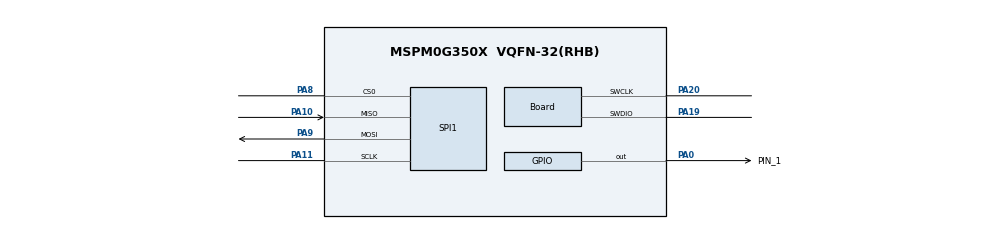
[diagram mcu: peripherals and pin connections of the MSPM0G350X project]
/**
 * @cliArgs --device "MSPM0G350X" --part "Default" --package "VQFN-32(RHB)" --product "mspm0_sdk@2.04.00.06"
 * @versions {"tool":"1.23.0+4000"}
 */

/**
 * Import the modules used in this configuration.
 */
const GPIO   = scripting.addModule("/ti/driverlib/GPIO", {}, false);
const GPIO1  = GPIO.addInstance();
const SPI    = scripting.addModule("/ti/driverlib/SPI", {}, false);
const SPI1   = SPI.addInstance();
const SYSCTL = scripting.addModule("/ti/driverlib/SYSCTL");

/**
 * Write custom configuration values to the imported modules.
 */
GPIO1.$name                              = "LED1";
GPIO1.associatedPins[0].$name            = "PIN_1";
GPIO1.associatedPins[0].internalResistor = "PULL_DOWN";
GPIO1.associatedPins[0].pin.$assign      = "PA0";

const Board                       = scripting.addModule("/ti/driverlib/Board", {}, false);
Board.peripheral.$assign          = "DEBUGSS";
Board.peripheral.swclkPin.$assign = "PA20";
Board.peripheral.swdioPin.$assign = "PA19";

SPI1.$name                              = "SPI";
SPI1.targetBitRate                      = 500000;
SPI1.peripheral.$assign                 = "SPI0";
SPI1.peripheral.sclkPin.$assign         = "PA11";
SPI1.peripheral.mosiPin.$assign         = "PA9";
SPI1.peripheral.misoPin.$assign         = "PA10";
SPI1.peripheral.cs0Pin.$assign          = "PA8";
SPI1.sclkPinConfig.$name                = "ti_driverlib_gpio_GPIOPinGeneric0";
SPI1.sclkPinConfig.direction            = scripting.forceWrite("OUTPUT");
SPI1.sclkPinConfig.onlyInternalResistor = scripting.forceWrite(false);
SPI1.sclkPinConfig.passedPeripheralType = scripting.forceWrite("Digital");
SPI1.mosiPinConfig.$name                = "ti_driverlib_gpio_GPIOPinGeneric1";
SPI1.mosiPinConfig.direction            = scripting.forceWrite("OUTPUT");
SPI1.mosiPinConfig.hideOutputInversion  = scripting.forceWrite(false);
SPI1.mosiPinConfig.onlyInternalResistor = scripting.forceWrite(false);
SPI1.mosiPinConfig.passedPeripheralType = scripting.forceWrite("Digital");
SPI1.misoPinConfig.$name                = "ti_driverlib_gpio_GPIOPinGeneric2";
SPI1.misoPinConfig.onlyInternalResistor = scripting.forceWrite(false);
SPI1.misoPinConfig.passedPeripheralType = scripting.forceWrite("Digital");
SPI1.cs0PinConfig.$name                 = "ti_driverlib_gpio_GPIOPinGeneric3";
SPI1.cs0PinConfig.direction             = scripting.forceWrite("OUTPUT");
SPI1.cs0PinConfig.hideOutputInversion   = scripting.forceWrite(false);
SPI1.cs0PinConfig.onlyInternalResistor  = scripting.forceWrite(false);
SPI1.cs0PinConfig.passedPeripheralType  = scripting.forceWrite("Digital");

SYSCTL.forceDefaultClkConfig = true;
SYSCTL.peripheral.$assign    = "SYSCTL";

const ProjectConfig              = scripting.addModule("/ti/project_config/ProjectConfig", {}, false);
ProjectConfig.migrationCondition = true;
